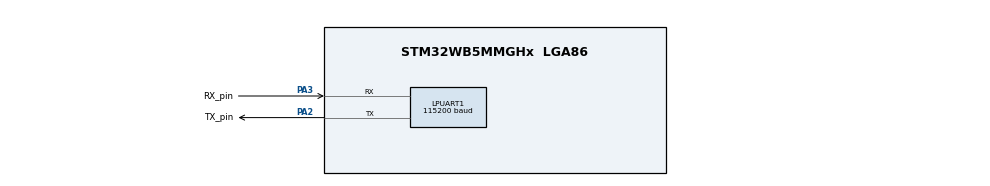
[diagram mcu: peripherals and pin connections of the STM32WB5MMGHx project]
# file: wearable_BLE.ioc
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LPUART1.BaudRate=115200
Mcu.Family=STM32WB
Mcu.Name=STM32WB5MMGHx
Mcu.Package=LGA86
NVIC.HSEM_IRQn=true\:0\:0\:false\:false\:true\:false\:true\:true
NVIC.IPCC_C1_RX_IRQn=true\:0\:0\:false\:false\:true\:true\:true\:true
NVIC.IPCC_C1_TX_IRQn=true\:0\:0\:false\:false\:true\:true\:true\:true
NVIC.LPUART1_IRQn=true\:0\:0\:false\:false\:true\:true\:true\:true
NVIC.PriorityGroup=NVIC_PRIORITYGROUP_4
NVIC.RCC_IRQn=true\:0\:0\:false\:false\:true\:true\:false\:true
NVIC.RTC_WKUP_IRQn=true\:0\:0\:false\:false\:true\:true\:true\:true
PA13.Mode=Serial_Wire
PA13.Signal=SYS_JTMS-SWDIO
PA14.Mode=Serial_Wire
PA14.Signal=SYS_JTCK-SWCLK
PA2.GPIO_Label=TX_pin
PA2.Mode=Asynchronous
PA2.Signal=LPUART1_TX
PA3.GPIO_Label=RX_pin
PA3.Mode=Asynchronous
PA3.Signal=LPUART1_RX
ProjectManager.HeapSize=0x200
ProjectManager.StackSize=0x400
ProjectManager.TargetToolchain=STM32CubeIDE
RCC.ADCFreq_Value=16000000
RCC.AHB2CLKDivider=RCC_SYSCLK_DIV2
RCC.AHBFreq_Value=64000000
RCC.APB1Freq_Value=64000000
RCC.APB1TimFreq_Value=64000000
RCC.APB2Freq_Value=64000000
RCC.APB2TimFreq_Value=64000000
RCC.APB3Freq_Value=16000000
RCC.CortexFreq_Value=64000000
RCC.HCLKFreq_Value=64000000
RCC.HSE_VALUE=32000000
RCC.HSI48_VALUE=48000000
RCC.HSI_VALUE=16000000
RCC.PLLN=48
RCC.PLLR=RCC_PLLR_DIV3
RCC.RFWKPClockSelection=RCC_RFWKPCLKSOURCE_LSE
RCC.RTCClockSelection=RCC_RTCCLKSOURCE_LSE
RCC.SYSCLKFreq_VALUE=64000000
RCC.SYSCLKSource=RCC_SYSCLKSOURCE_PLLCLK
RCC.USBFreq_Value=16000000
RCC.VCOOutputFreq_Value=192000000
STM32_WPAN.AD_TYPE_COMPLETE_LOCAL_NAME=HM-STM32
STM32_WPAN.AD_TYPE_SHORTENED_LOCAL_NAME=HM
STM32_WPAN.AD_TYPE_SHORTENED_LOCAL_NAME_LENGTH=3
STM32_WPAN.BT_SIG_HEALTH_THERMOMETER_SENSOR=Disabled
STM32_WPAN.CFG_BONDING_MODE=1
STM32_WPAN.CFG_LSCLK_LSE=0
STM32_WPAN.CUSTOM_P2P_SERVER=Disabled
STM32_WPAN.CUSTOM_TEMPLATE=Enabled
STM32_WPAN.INCLUDE_AD_TYPE_COMPLETE_LOCAL_NAME=1
STM32_WPAN.INCLUDE_AD_TYPE_SHORTENED_LOCAL_NAME=1
STM32_WPAN.NUMBER_OF_SERVICES=1
STM32_WPAN.PAIRING_PARAMETERS=OFF
STM32_WPAN.SERVICE1_CHAR1_GATT_NOTIFY_READ_REQ_AND_WAIT_FOR_APPL_RESP=\ 
STM32_WPAN.SERVICE1_CHAR1_GATT_NOTIFY_WRITE_REQ_AND_WAIT_FOR_APPL_RESP=\ 
STM32_WPAN.SERVICE1_CHAR1_LONG_NAME=CharWrite
STM32_WPAN.SERVICE1_CHAR1_PROP_WRITE=CHAR_PROP_WRITE
STM32_WPAN.SERVICE1_CHAR1_SHORT_NAME=CharWrite
STM32_WPAN.SERVICE1_CHAR1_VALUE_LENGTH=7
STM32_WPAN.SERVICE1_CHAR2_LONG_NAME=CharNotify
STM32_WPAN.SERVICE1_CHAR2_PROP_NOTIFY=CHAR_PROP_NOTIFY
STM32_WPAN.SERVICE1_CHAR2_SHORT_NAME=CharNotify
STM32_WPAN.SERVICE1_CHAR2_UUID=00 01
STM32_WPAN.SERVICE1_CHAR2_VALUE_LENGTH=12
STM32_WPAN.SERVICE1_LONG_NAME=HealthMonitoringS
STM32_WPAN.SERVICE1_NUMBER_OF_CHARACTERISTICS=2
STM32_WPAN.SERVICE1_SHORT_NAME=HM
VP_HSEM_VS_HSEM.Mode=HSEM_Activate
VP_IPCC_VS_IPCC.Mode=IPCC_Activate
VP_MEMORYMAP_VS_MEMORYMAP.Mode=CurAppReg
VP_RCC_V_OSC32_IN.Mode=LSE-External-Clock-Source
VP_RCC_V_OSC_IN.Mode=HSE-External-Clock-Source
VP_RF_VS_RF.Mode=RF_Activate
VP_RTC_VS_RTC_Activate.Mode=RTC_Enabled
VP_RTC_VS_RTC_WakeUp_intern.Mode=WakeUp
VP_SEQUENCER_VS_SEQUENCER.Mode=SEQUENCER_Enabled
VP_STM32_WPAN_VS_BLE_HOST.Mode=STM32_WPAN_Enabled
VP_TINY_LPM_VS_TINY_LPM.Mode=TINY_LPM_Enabled
board=custom

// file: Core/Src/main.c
/* USER CODE BEGIN Header */
/**
  ******************************************************************************
  * @file           : main.c
  * @brief          : Main program body
  ******************************************************************************
  * @attention
  *
  * Copyright (c) 2025 STMicroelectronics.
  * All rights reserved.
  *
  * This software is licensed under terms that can be found in the LICENSE file
  * in the root directory of this software component.
  * If no LICENSE file comes with this software, it is provided AS-IS.
  *
  ******************************************************************************
  */
/* USER CODE END Header */
#include "main.h"

/* USER CODE BEGIN Includes */
#include "data_handler.h"
#include "uart_handler.h"
/* USER CODE END Includes */

IPCC_HandleTypeDef hipcc;

UART_HandleTypeDef hlpuart1;

RTC_HandleTypeDef hrtc;

void SystemClock_Config(void);
void PeriphCommonClock_Config(void);
static void MX_GPIO_Init(void);
static void MX_LPUART1_UART_Init(void);
static void MX_RTC_Init(void);
static void MX_IPCC_Init(void);
static void MX_RF_Init(void);

int main(void)
{

  /* MCU Configuration--------------------------------------------------------*/

  /* Reset of all peripherals, Initializes the Flash interface and the Systick. */
  HAL_Init();
  /* Config code for STM32_WPAN (HSE Tuning must be done before system clock configuration) */
  MX_APPE_Config();

  /* Configure the system clock */
  SystemClock_Config();

  /* Configure the peripherals common clocks */
  PeriphCommonClock_Config();

  /* IPCC initialisation */
  MX_IPCC_Init();

  /* Initialize all configured peripherals */
  MX_GPIO_Init();
  MX_LPUART1_UART_Init();
  MX_RTC_Init();
  MX_RF_Init();
  /* USER CODE BEGIN 2 */
  data_handler_Init();
  uart_handler_Init(&hlpuart1);

  /* USER CODE END 2 */

  /* Init code for STM32_WPAN */
  MX_APPE_Init();

  /* Infinite loop */
  while (1)
  {
    MX_APPE_Process();

  }
}

void SystemClock_Config(void)
{
  RCC_OscInitTypeDef RCC_OscInitStruct = {0};
  RCC_ClkInitTypeDef RCC_ClkInitStruct = {0};

  /** Configure LSE Drive Capability
  */
  HAL_PWR_EnableBkUpAccess();
  __HAL_RCC_LSEDRIVE_CONFIG(RCC_LSEDRIVE_MEDIUMHIGH);

  /** Configure the main internal regulator output voltage
  */
  __HAL_PWR_VOLTAGESCALING_CONFIG(PWR_REGULATOR_VOLTAGE_SCALE1);

  /** Initializes the RCC Oscillators according to the specified parameters
  * in the RCC_OscInitTypeDef structure.
  */
  RCC_OscInitStruct.OscillatorType = RCC_OSCILLATORTYPE_HSI|RCC_OSCILLATORTYPE_HSE
                              |RCC_OSCILLATORTYPE_LSE|RCC_OSCILLATORTYPE_MSI;
  RCC_OscInitStruct.HSEState = RCC_HSE_ON;
  RCC_OscInitStruct.LSEState = RCC_LSE_ON;
  RCC_OscInitStruct.HSIState = RCC_HSI_ON;
  RCC_OscInitStruct.MSIState = RCC_MSI_ON;
  RCC_OscInitStruct.HSICalibrationValue = RCC_HSICALIBRATION_DEFAULT;
  RCC_OscInitStruct.MSICalibrationValue = RCC_MSICALIBRATION_DEFAULT;
  RCC_OscInitStruct.MSIClockRange = RCC_MSIRANGE_6;
  RCC_OscInitStruct.PLL.PLLState = RCC_PLL_ON;
  RCC_OscInitStruct.PLL.PLLSource = RCC_PLLSOURCE_MSI;
  RCC_OscInitStruct.PLL.PLLM = RCC_PLLM_DIV1;
  RCC_OscInitStruct.PLL.PLLN = 48;
  RCC_OscInitStruct.PLL.PLLP = RCC_PLLP_DIV2;
  RCC_OscInitStruct.PLL.PLLR = RCC_PLLR_DIV3;
  RCC_OscInitStruct.PLL.PLLQ = RCC_PLLQ_DIV2;
  if (HAL_RCC_OscConfig(&RCC_OscInitStruct) != HAL_OK)
  {
    Error_Handler();
  }

  /** Configure the SYSCLKSource, HCLK, PCLK1 and PCLK2 clocks dividers
  */
  RCC_ClkInitStruct.ClockType = RCC_CLOCKTYPE_HCLK4|RCC_CLOCKTYPE_HCLK2
                              |RCC_CLOCKTYPE_HCLK|RCC_CLOCKTYPE_SYSCLK
                              |RCC_CLOCKTYPE_PCLK1|RCC_CLOCKTYPE_PCLK2;
  RCC_ClkInitStruct.SYSCLKSource = RCC_SYSCLKSOURCE_PLLCLK;
  RCC_ClkInitStruct.AHBCLKDivider = RCC_SYSCLK_DIV1;
  RCC_ClkInitStruct.APB1CLKDivider = RCC_HCLK_DIV1;
  RCC_ClkInitStruct.APB2CLKDivider = RCC_HCLK_DIV1;
  RCC_ClkInitStruct.AHBCLK2Divider = RCC_SYSCLK_DIV2;
  RCC_ClkInitStruct.AHBCLK4Divider = RCC_SYSCLK_DIV1;

  if (HAL_RCC_ClockConfig(&RCC_ClkInitStruct, FLASH_LATENCY_3) != HAL_OK)
  {
    Error_Handler();
  }
}

void PeriphCommonClock_Config(void)
{
  RCC_PeriphCLKInitTypeDef PeriphClkInitStruct = {0};

  /** Initializes the peripherals clock
  */
  PeriphClkInitStruct.PeriphClockSelection = RCC_PERIPHCLK_SMPS|RCC_PERIPHCLK_RFWAKEUP;
  PeriphClkInitStruct.RFWakeUpClockSelection = RCC_RFWKPCLKSOURCE_LSE;
  PeriphClkInitStruct.SmpsClockSelection = RCC_SMPSCLKSOURCE_HSI;
  PeriphClkInitStruct.SmpsDivSelection = RCC_SMPSCLKDIV_RANGE1;

  if (HAL_RCCEx_PeriphCLKConfig(&PeriphClkInitStruct) != HAL_OK)
  {
    Error_Handler();
  }
}

static void MX_IPCC_Init(void)
{

  hipcc.Instance = IPCC;
  if (HAL_IPCC_Init(&hipcc) != HAL_OK)
  {
    Error_Handler();
  }

}

static void MX_LPUART1_UART_Init(void)
{

  hlpuart1.Instance = LPUART1;
  hlpuart1.Init.BaudRate = 115200;
  hlpuart1.Init.WordLength = UART_WORDLENGTH_8B;
  hlpuart1.Init.StopBits = UART_STOPBITS_1;
  hlpuart1.Init.Parity = UART_PARITY_NONE;
  hlpuart1.Init.Mode = UART_MODE_TX_RX;
  hlpuart1.Init.HwFlowCtl = UART_HWCONTROL_NONE;
  hlpuart1.Init.OneBitSampling = UART_ONE_BIT_SAMPLE_DISABLE;
  hlpuart1.Init.ClockPrescaler = UART_PRESCALER_DIV1;
  hlpuart1.AdvancedInit.AdvFeatureInit = UART_ADVFEATURE_NO_INIT;
  hlpuart1.FifoMode = UART_FIFOMODE_DISABLE;
  if (HAL_UART_Init(&hlpuart1) != HAL_OK)
  {
    Error_Handler();
  }
  if (HAL_UARTEx_SetTxFifoThreshold(&hlpuart1, UART_TXFIFO_THRESHOLD_1_8) != HAL_OK)
  {
    Error_Handler();
  }
  if (HAL_UARTEx_SetRxFifoThreshold(&hlpuart1, UART_RXFIFO_THRESHOLD_1_8) != HAL_OK)
  {
    Error_Handler();
  }
  if (HAL_UARTEx_DisableFifoMode(&hlpuart1) != HAL_OK)
  {
    Error_Handler();
  }

}

static void MX_RF_Init(void)
{

}

static void MX_RTC_Init(void)
{

  /** Initialize RTC Only
  */
  hrtc.Instance = RTC;
  hrtc.Init.HourFormat = RTC_HOURFORMAT_24;
  hrtc.Init.AsynchPrediv = CFG_RTC_ASYNCH_PRESCALER;
  hrtc.Init.SynchPrediv = CFG_RTC_SYNCH_PRESCALER;
  hrtc.Init.OutPut = RTC_OUTPUT_DISABLE;
  hrtc.Init.OutPutPolarity = RTC_OUTPUT_POLARITY_HIGH;
  hrtc.Init.OutPutType = RTC_OUTPUT_TYPE_OPENDRAIN;
  hrtc.Init.OutPutRemap = RTC_OUTPUT_REMAP_NONE;
  if (HAL_RTC_Init(&hrtc) != HAL_OK)
  {
    Error_Handler();
  }

  /** Enable the WakeUp
  */
  if (HAL_RTCEx_SetWakeUpTimer_IT(&hrtc, 0, RTC_WAKEUPCLOCK_RTCCLK_DIV16) != HAL_OK)
  {
    Error_Handler();
  }

}

static void MX_GPIO_Init(void)
{

  /* GPIO Ports Clock Enable */
  __HAL_RCC_GPIOA_CLK_ENABLE();

}

void Error_Handler(void)
{
  __disable_irq();
  while (1)
  {
  }
}
